# MIK32 register map
Vendor: Mikron JSC; Series: MIK32; File version: 1.0
Registers are 32-bit, read-write, reset 0x0 unless marked. A register's access mark holds for its fields unless they carry their own. Offsets are from the block's base; [hi:lo] are bit positions; 'fields as' and 'values as' point back to an identical list.

## SPIFI_CONFIG — Контроллер SPIFI
Base 0x00070000
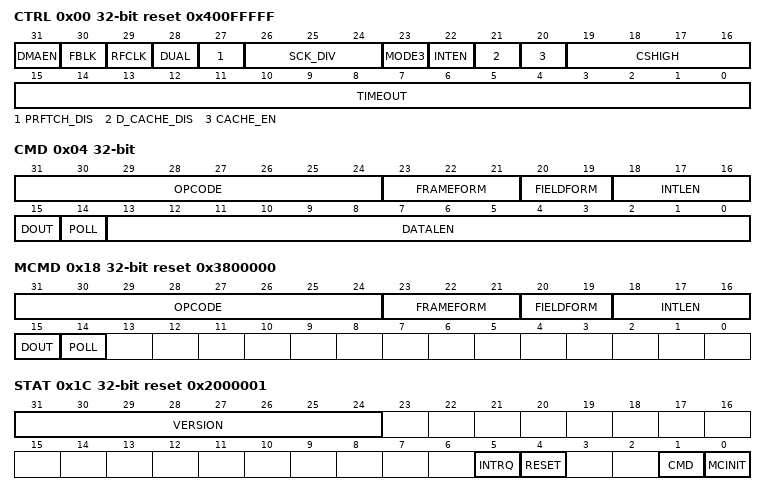
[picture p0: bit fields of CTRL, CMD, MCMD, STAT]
0x00 CTRL reset 0x400FFFFF — SPIFI регистр управления
  [31] DMAEN — Бит разрешения запросов DMA от контроллера SPIFI Устанавливать только в периферийном режиме
    0=Disable (Запросы запрещены); 1=Enable (Запросы разрешены)
  [30] FBLK — Бит выбора сигнала стробирования входных данных с выходного буфера тактового сигнала
    0=Internal_signal (Внутренний сигнал); 1=External_signal (Внешний сигнал)
  [29] RFCLK — Бит выбора активного перепада сигнала для стробирования входных данных
    0=Rising_edge (Положительный перепад); 1=Falling_edge (Отрицательный перепад)
  [28] DUAL — Бит выбора протокола: сигналы IO[3:0] – (0–4) битовый протокол; сигналы IO[1:0] – (1–2) битовый протокол
    0=Single_or_quad (Сигналы IO[3:0] – (0–4) битовый протокол); 1=Dual (Сигналы IO[1:0] – (1–2) битовый протокол)
  [27] PRFTCH_DIS — Бит разрешения упреждающих выборок кэш памяти «0» – выборки разрешены
    0=Enable (Выборки разрешены); 1=Disable (Выборки запрещены)
  [26:24] SCK_DIV — Делитель для получения тактового сигнала SPIFI_SCK из системного тактового сигнала HCLK. Частота рассчитывается по формуле: FSPIFI_SCK = FHCLK / 2^(SCK_DIV+1)
  [23] MODE3 — Бит режима 3
    0=MODE0 (Режим 0 (CPOL = 0, CPHA = 0). CPOL = 0 - исходное состояние сигнала синхронизации — низкий уровень CPHA = 0 - выборка данных производится по переднему фронту (переключению) сигнала синхронизации); 1=MODE3 (Режим 3 (CPOL = 1, CPHA = 1). CPHA = 1 - исходное состояние сигнала синхронизации — высокий уровень CPOL = 1 - выборка данных производится по заднему фронту (переключению) сигнала синхронизации)
  [22] INTEN — Бит разрешения прерывания при завершении выполнения команды (если этот бит равен «1», то прерывание разрешено)
    0=Disable (Прерывнаие запрещено); 1=Enable (Прерывание разрешено)
  [21] D_CACHE_DIS — Бит запрещения кеширования данных (транзакций AHB, для которых сигнал HPROT[0:0] = 1)
    0=Data_is_cached (При разрешенном кэшировании кэширование данных выполняется); 1=Data_is_not_cached (Данные не кэшируются)
  [20] CACHE_EN — Бит разрешения кэширования
    0=Disable (Кэширование отключено); 1=Enable (Кэширование включено)
  [19:16] CSHIGH — Количество периодов сигнала SPIFI_SCK минус один, в течение которых сигнал SPIFI_CS остается в неактивном состоянии перед началом выполнения команды
  [15:0] TIMEOUT — Количество периодов сигнала SPIFI_SCK без чтения данных в режиме работы с памятью, которое вызывает завершение выполнения команды установкой сигнала SPIFI_CS в состояние «1» и сбросом бита CMD
0x04 CMD — SPIFI регистр команд. Этот регистр может быть записан только тогда, когда биты CMD и MCINIT равны нулю
  [31:24] OPCODE — Код операции (не используется для некоторых значений поля FRAMEFORM)
  [23:21] FRAMEFORM — Бит управления полями кода операции и адреса команды
    1=OPCODE_NOADDR (Выдается только код операции, адреса нет); 2=OPCODE_1ADDR (Код операции и младший байт адреса); 3=OPCODE_2ADDR (Код операции и два младших байта адреса); 4=OPCODE_3ADDR (Код операции и три младших байта адреса); 5=OPCODE_4ADDR (Код операции и 4 байта адреса); 6=NOOPCODE_3ADDR (Нет кода операции, три младших байта адреса); 7=NOOPCODE_4ADDR (Нет кода операции, 4 байта адреса)
  [20:19] FIELDFORM — Формат вывода полей команды
    0=All_serial (Все поля выводятся в последовательном режиме); 1=Data_parallel (Данные выводятся в четырех или двух битовом режиме, а остальные поля в последовательном режиме); 2=Opcode_serial (Код операции выводится в последовательном режиме, а остальные в четырех или двух битовом); 3=All_parallel (Все поля в четырех или двух битовом режиме)
  [18:16] INTLEN — Количество байт промежуточных данных, которые хранятся в регистре IDATA. Если количество байт больше, чем может хранить регистр IDATA, то остаток добивается нулевыми значениями
  [15] DOUT — Бит направления передачи данных. «0» – чтение из флэш
    0=Read (Чтение из флэш); 1=Write (Запись во флэш)
  [14] POLL — Бит должен быть установлен при выполнении команды, которая содержит входное поле данных и циклически запрашивает состояние бита входного потока битов из регистра статуса флеш-памяти. Номер проверяемого бита в байте статуса должен быть указан в битах DATALEN[2:0], а требуемое значение бита – в бите DATALEN[3]. Как только значения этих битов станут равны, контроллер завершает выполнение текущей команды, деактивируя сигнал SPIFI_CS, и формирует прерывание, если оно разрешено. После завершения процесса поллинга необходимо считать один байт из регистра DATA, так как в нем сохряняется последний принятый статус FLASH.
    0=Disable (Режим поллинга выключен); 1=Enable (Режим поллинга включен)
  [13:0] DATALEN — В тех случаях, когда бит POLL равен «0», это поле определяет количество байт данных при выполнении команды. Если это поле равно «0», то выполняемая команда не содержит данных
0x08 ADDRESS — SPIFI регистр адреса. Данный регистр должен быть настроен перед инициализацией любой команды. При выполнении команды первым выводится старший бит адреса
  [31:0] ADDRESS — Исполнительный адрес команды
0x0C IDATA — SPIFI регистр промежуточных данных. Данный регистр должен быть настроен перед инициализацией команды, в которой используются промежуточные данные. При выполнении команды первым выводится младший бит слова
  [31:0] IDATA — Промежуточные данные
0x10 CLIMIT — SPIFI регистр верхней границы адреса кеширования
  [31:0] CLIMIT — Верхний предел кэшируемой памяти
0x14 DATA — SPIFI регистр данных 32 бита. Если выходной буфер чтения пуст или входной буфер записи полон, то при отправке запроса по шине AHB будет вызвано исключение (код 5 "Load access fault").
  [31:0] DATA — Входные или выходные данные
0x14 DATA8 (alternate view of DATA) — SPIFI регистр данных 8 бит. Если выходной буфер чтения пуст или входной буфер записи полон, то при отправке запроса по шине AHB будет вызвано исключение (код 5 "Load access fault").
  [7:0] DATA8 — Входные или выходные данные
0x14 DATA16 (alternate view of DATA) — SPIFI регистр данных 16 бит. Если выходной буфер чтения пуст или входной буфер записи полон, то при отправке запроса по шине AHB будет вызвано исключение (код 5 "Load access fault").
  [15:0] DATA16 — Входные или выходные данные
0x14 DATA32 (alternate view of DATA) — SPIFI регистр данных 32 бита. Если выходной буфер чтения пуст или входной буфер записи полон, то при отправке запроса по шине AHB будет вызвано исключение (код 5 "Load access fault").
  [31:0] DATA32 — Входные или выходные данные
0x18 MCMD reset 0x3800000 — SPIFI регистр команд памяти
  [31:24] OPCODE — Код операции (не используется для некоторых значений поля FRAMEFORM)
  [23:21] FRAMEFORM — Бит управления полями кода операции и адреса команды
    values as CMD.FRAMEFORM
  [20:19] FIELDFORM — Формат вывода полей команды
    values as CMD.FIELDFORM
  [18:16] INTLEN — Кол-во байт промежуточных данных (они хранятся в регистре IDATA). Если кол-во байт больше, чем может хранить регистр IDATA, остаток заполняется нулевыми значениями
  [15] DOUT — Бит должен быть установлен в «0»
    0=Read (Чтение из флэш)
  [14] POLL — Бит должен быть установлен в «0»
    0=Disable (Режим поллинга выключен)
0x1C STAT reset 0x2000001 — SPIFI регистр статуса
  [31:24] VERSION ro — Версия контроллера SPIFI (поле доступно только для чтения)
  [5] INTRQ — Запись «1» в бит сбрасывает запрос на прерывание от контроллера SPIFI
    on write: 1=Clear_interrupt (Сбрость запрос на прерывание от контроллера SPIFI)
  [4] RESET — Бит предназначен для того, чтобы прервать текущую команду периферийного режима или режима памяти. Бит сбрасывается, когда контроллер готов к выполнению новой команды
    0=Ready (Контроллер готов к выполнению новой команды); 1=Reset (Прервать текущую команду периферийного режима или режима памяти)
  [1] CMD — Бит устанавливается в «1», если программное обеспечение успешно записало регистр команд. Сброс этого бита осуществляется теми же сигналами, что и бит MCINIT. Также сброс бита CMD происходит при завершении выполнения команды, когда деактивируется сигнал SPIFI_CS
    0=Idle (Программное обеспечение не записало регистр команд); 1=Success (Программное обеспечение успешно записало регистр команд)
  [0] MCINIT ro — Бит устанавливается в «1», если программное обеспечение успешно записало регистр команд памяти. Сброс бита осуществляется аппаратным сбросом или установкой в «1» бита RESET
    0=Idle (Программное обеспечение не записало регистр команд памяти); 1=Success (Программное обеспечение успешно записало регистр команд памяти)
